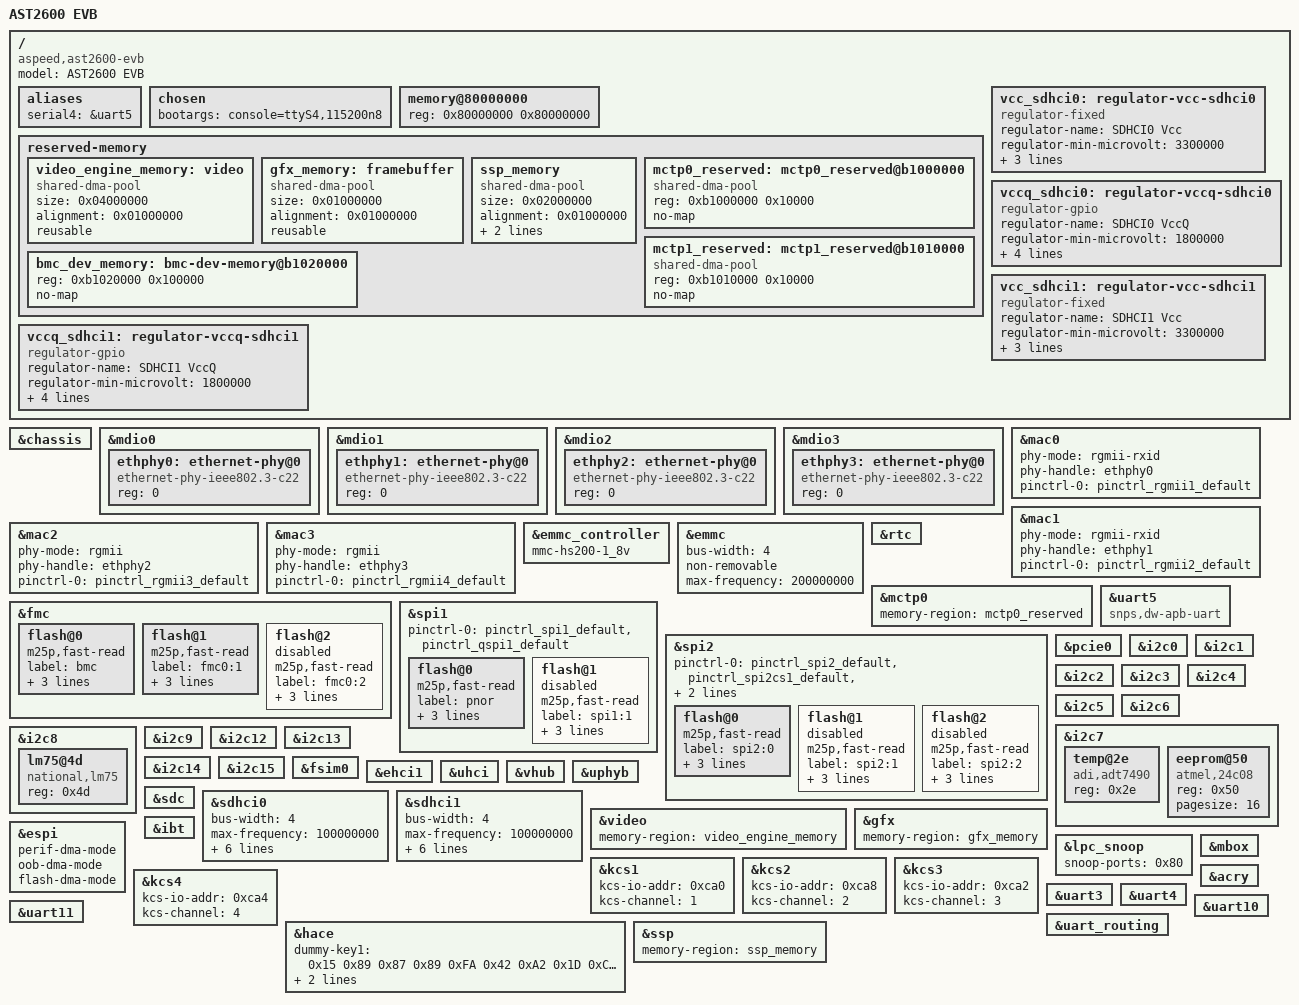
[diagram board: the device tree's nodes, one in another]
// SPDX-License-Identifier: GPL-2.0-or-later
// Copyright 2019 IBM Corp.

/dts-v1/;

#include "aspeed-g6.dtsi"
#include <dt-bindings/gpio/aspeed-gpio.h>

/ {
	model = "AST2600 EVB";
	compatible = "aspeed,ast2600-evb", "aspeed,ast2600";

	aliases {
		serial4 = &uart5;
	};

	chosen {
		bootargs = "console=ttyS4,115200n8";
	};

	memory@80000000 {
		device_type = "memory";
		reg = <0x80000000 0x80000000>;
	};

	reserved-memory {
		#address-cells = <1>;
		#size-cells = <1>;
		ranges;

		video_engine_memory: video {
			size = <0x04000000>;
			alignment = <0x01000000>;
			compatible = "shared-dma-pool";
			reusable;
		};

		gfx_memory: framebuffer {
			size = <0x01000000>;
			alignment = <0x01000000>;
			compatible = "shared-dma-pool";
			reusable;
		};

		ssp_memory: ssp_memory {
			size = <0x02000000>;
			alignment = <0x01000000>;
			shm-size = <0x1000>;
			compatible = "shared-dma-pool";
			no-map;
		};

		mctp0_reserved: mctp0_reserved@b1000000 {
			reg = <0xb1000000 0x10000>;
			compatible = "shared-dma-pool";
			no-map;
		};

		mctp1_reserved: mctp1_reserved@b1010000 {
			reg = <0xb1010000 0x10000>;
			compatible = "shared-dma-pool";
			no-map;
		};

		bmc_dev_memory: bmc-dev-memory@b1020000 {
			reg = <0xb1020000 0x100000>;
			no-map;
		};
	};

	vcc_sdhci0: regulator-vcc-sdhci0 {
		compatible = "regulator-fixed";
		regulator-name = "SDHCI0 Vcc";
		regulator-min-microvolt = <3300000>;
		regulator-max-microvolt = <3300000>;
		gpios = <&gpio0 ASPEED_GPIO(V, 0) GPIO_ACTIVE_HIGH>;
		enable-active-high;
	};

	vccq_sdhci0: regulator-vccq-sdhci0 {
		compatible = "regulator-gpio";
		regulator-name = "SDHCI0 VccQ";
		regulator-min-microvolt = <1800000>;
		regulator-max-microvolt = <3300000>;
		gpios = <&gpio0 ASPEED_GPIO(V, 1) GPIO_ACTIVE_HIGH>;
		gpios-states = <1>;
		states = <3300000 1>,
			 <1800000 0>;
	};

	vcc_sdhci1: regulator-vcc-sdhci1 {
		compatible = "regulator-fixed";
		regulator-name = "SDHCI1 Vcc";
		regulator-min-microvolt = <3300000>;
		regulator-max-microvolt = <3300000>;
		gpios = <&gpio0 ASPEED_GPIO(V, 2) GPIO_ACTIVE_HIGH>;
		enable-active-high;
	};

	vccq_sdhci1: regulator-vccq-sdhci1 {
		compatible = "regulator-gpio";
		regulator-name = "SDHCI1 VccQ";
		regulator-min-microvolt = <1800000>;
		regulator-max-microvolt = <3300000>;
		gpios = <&gpio0 ASPEED_GPIO(V, 3) GPIO_ACTIVE_HIGH>;
		gpios-states = <1>;
		states = <3300000 1>,
			 <1800000 0>;
	};
};

&chassis {
	status = "okay";
};

&mdio0 {
	status = "okay";

	ethphy0: ethernet-phy@0 {
		compatible = "ethernet-phy-ieee802.3-c22";
		reg = <0>;
	};
};

&mdio1 {
	status = "okay";

	ethphy1: ethernet-phy@0 {
		compatible = "ethernet-phy-ieee802.3-c22";
		reg = <0>;
	};
};

&mdio2 {
	status = "okay";

	ethphy2: ethernet-phy@0 {
		compatible = "ethernet-phy-ieee802.3-c22";
		reg = <0>;
	};
};

&mdio3 {
	status = "okay";

	ethphy3: ethernet-phy@0 {
		compatible = "ethernet-phy-ieee802.3-c22";
		reg = <0>;
	};
};

&mac0 {
	status = "okay";

	phy-mode = "rgmii-rxid";
	phy-handle = <&ethphy0>;

	pinctrl-names = "default";
	pinctrl-0 = <&pinctrl_rgmii1_default>;
};


&mac1 {
	status = "okay";

	phy-mode = "rgmii-rxid";
	phy-handle = <&ethphy1>;

	pinctrl-names = "default";
	pinctrl-0 = <&pinctrl_rgmii2_default>;
};

&mac2 {
	status = "okay";

	phy-mode = "rgmii";
	phy-handle = <&ethphy2>;

	pinctrl-names = "default";
	pinctrl-0 = <&pinctrl_rgmii3_default>;
};

&mac3 {
	status = "okay";

	phy-mode = "rgmii";
	phy-handle = <&ethphy3>;

	pinctrl-names = "default";
	pinctrl-0 = <&pinctrl_rgmii4_default>;
};

&emmc_controller {
	status = "okay";
	mmc-hs200-1_8v;
};

&emmc {
	status = "okay";
#if 1
	bus-width = <4>;
#else
	bus-width = <8>;
	pinctrl-0 = <&pinctrl_emmc_default
		     &pinctrl_emmcg8_default>;
#endif
	non-removable;
	max-frequency = <200000000>;
};

&rtc {
	status = "okay";
};

&mctp0 {
	status = "okay";
	memory-region = <&mctp0_reserved>;
};

&fmc {
	status = "okay";
	flash@0 {
		status = "okay";
		m25p,fast-read;
		label = "bmc";
		spi-rx-bus-width = <4>;
		spi-tx-bus-width = <4>;
		spi-max-frequency = <50000000>;
#include "aspeed-evb-flash-layout-64.dtsi"
	};

	flash@1 {
		status = "okay";
		m25p,fast-read;
		label = "fmc0:1";
		spi-rx-bus-width = <4>;
		spi-tx-bus-width = <4>;
		spi-max-frequency = <50000000>;
	};

	flash@2 {
		status = "disabled";
		m25p,fast-read;
		label = "fmc0:2";
		spi-rx-bus-width = <4>;
		spi-tx-bus-width = <4>;
		spi-max-frequency = <50000000>;
	};
};

&spi1 {
	status = "okay";
	pinctrl-names = "default";
	pinctrl-0 = <&pinctrl_spi1_default &pinctrl_qspi1_default>;

	flash@0 {
		status = "okay";
		m25p,fast-read;
		label = "pnor";
		spi-rx-bus-width = <4>;
		spi-tx-bus-width = <4>;
		spi-max-frequency = <100000000>;
	};

	flash@1 {
		status = "disabled";
		m25p,fast-read;
		label = "spi1:1";
		spi-rx-bus-width = <4>;
		spi-tx-bus-width = <4>;
		spi-max-frequency = <50000000>;
	};
};

&spi2 {
	status = "okay";
	pinctrl-names = "default";
	pinctrl-0 = <&pinctrl_spi2_default &pinctrl_spi2cs1_default
				 &pinctrl_spi2cs2_default &pinctrl_qspi2_default>;

	flash@0 {
		status = "okay";
		m25p,fast-read;
		label = "spi2:0";
		spi-tx-bus-width = <4>;
		spi-rx-bus-width = <4>;
		spi-max-frequency = <50000000>;
	};

	flash@1 {
		status = "disabled";
		m25p,fast-read;
		label = "spi2:1";
		spi-tx-bus-width = <4>;
		spi-rx-bus-width = <4>;
		spi-max-frequency = <50000000>;
	};

	flash@2 {
		status = "disabled";
		m25p,fast-read;
		label = "spi2:2";
		spi-tx-bus-width = <4>;
		spi-rx-bus-width = <4>;
		spi-max-frequency = <50000000>;
	};
};

&uart5 {
	// Workaround for A0
	compatible = "snps,dw-apb-uart";
};

#if 0
&bmc_dev {
	status = "okay";
	memory-region = <&bmc_dev_memory>;
};
#endif

&pcie0 {
	status = "okay";
};

&i2c0 {
	status = "okay";
};

&i2c1 {
	status = "okay";
};

&i2c2 {
	status = "okay";
};

&i2c3 {
	status = "okay";
};

&i2c4 {
	status = "okay";
};

&i2c5 {
	status = "okay";
};

&i2c6 {
	status = "okay";
};

&i2c7 {
	status = "okay";

	temp@2e {
		compatible = "adi,adt7490";
		reg = <0x2e>;
	};

	eeprom@50 {
		compatible = "atmel,24c08";
		reg = <0x50>;
		pagesize = <16>;
	};
};

&i2c8 {
	status = "okay";

	lm75@4d {
		compatible = "national,lm75";
		reg = <0x4d>;
	};
};

&i2c9 {
	status = "okay";
};

&i2c12 {
	status = "okay";
};

&i2c13 {
	status = "okay";
};

&i2c14 {
	status = "okay";
};

&i2c15 {
	status = "okay";
};

&fsim0 {
	status = "okay";
};

#if 0
&ehci0 {
	status = "okay";
};
#endif

&ehci1 {
	status = "okay";
};

&uhci {
	status = "okay";
};

&vhub {
	status = "okay";
	pinctrl-names = "default";
#if 0
	pinctrl-0 = <&pinctrl_usb2adp_default>;
#endif
};

#if 0
&udc {
	status = "okay";
	pinctrl-names = "default";
	pinctrl-0 = <&pinctrl_usb2bd_default>;
};
#endif

&uphyb {
	status = "okay";
};

&sdc {
	status = "okay";
};

/*
 * The signal voltage of sdhci0 and sdhci1 on AST2600-A2 EVB is able to be
 * toggled by GPIO pins.
 * In the reference design, GPIOV0 of AST2600-A2 EVB is connected to the
 * power load switch that provides 3.3v to sdhci0 vdd, GPIOV1 is connected to
 * a 1.8v and a 3.3v power load switch that provides signal voltage to
 * sdhci0 bus.
 * If GPIOV0 is active high, sdhci0 is enabled, otherwise, sdhci0 is disabled.
 * If GPIOV1 is active high, 3.3v power load switch is enabled, sdhci0 signal
 * voltage is 3.3v, otherwise, 1.8v power load switch will be enabled,
 * sdhci0 signal voltage becomes 1.8v.
 * AST2600-A2 EVB also supports toggling signal voltage for sdhci1.
 * The design is the same as sdhci0, it uses GPIOV2 as power-gpio and GPIOV3
 * as power-switch-gpio.
 */
&sdhci0 {
	status = "okay";
	bus-width = <4>;
	max-frequency = <100000000>;
	sdhci-drive-type = /bits/ 8 <3>;
	sdhci-caps-mask = <0x7 0x0>;
	sdhci,wp-inverted;
	vmmc-supply = <&vcc_sdhci0>;
	vqmmc-supply = <&vccq_sdhci0>;
	clk-phase-sd-hs = <7>, <200>;
};

&sdhci1 {
	status = "okay";
	bus-width = <4>;
	max-frequency = <100000000>;
	sdhci-drive-type = /bits/ 8 <3>;
	sdhci-caps-mask = <0x7 0x0>;
	sdhci,wp-inverted;
	vmmc-supply = <&vcc_sdhci1>;
	vqmmc-supply = <&vccq_sdhci1>;
	clk-phase-sd-hs = <7>, <200>;
};

&video {
	status = "okay";
	memory-region = <&video_engine_memory>;
};

&gfx {
	status = "okay";
	memory-region = <&gfx_memory>;
};

&espi {
	status = "okay";
	perif-dma-mode;
	oob-dma-mode;
	flash-dma-mode;
};

#if 1
&lpc_snoop {
	status = "okay";
	snoop-ports = <0x80>;
};
#else
&lpc_pcc {
	status = "okay";
	pcc-ports = <0x80>;
};
#endif

&ibt {
	status = "okay";
};

&kcs1 {
	kcs-io-addr = <0xca0>;
	kcs-channel = <1>;
	status = "okay";
};

&kcs2 {
	kcs-io-addr = <0xca8>;
	kcs-channel = <2>;
	status = "okay";
};

&kcs3 {
	status = "okay";
	kcs-io-addr = <0xca2>;
	kcs-channel = <3>;
};

&kcs4 {
	status = "okay";
	kcs-io-addr = <0xca4>;
	kcs-channel = <4>;
};

&mbox {
	status = "okay";
};

&hace {
	status = "okay";
	dummy-key1 = /bits/ 8 <0x15 0x89 0x87 0x89 0xFA 0x42 0xA2 0x1D 0xCE 0x85 0x78 0x1A 0x39 0xFA 0xD7 0x5B 0xFD 0x65 0x32 0xC5 0x25 0x6B 0x34 0xCC 0xEE 0x70 0x03 0x23 0x29 0x06 0x57 0xD0>;
	dummy-key2 = /bits/ 8 <0x02 0x89 0x87 0x89 0xFA 0x42 0xA2 0x1D 0xCE 0x85 0x78 0x1A 0x39 0xFA 0xD7 0x5B 0xFD 0x65 0x32 0xC5 0x25 0x6B 0x34 0xCC 0xEE 0x70 0x03 0x23 0x29 0x06 0x57 0xD0>;
};

&acry {
	status = "okay";
};

&uart3 {
	status = "okay";
};

&uart4 {
	status = "okay";
};

&uart10 {
	status = "okay";
};

&uart11 {
	status = "okay";
};

&uart_routing {
	status = "okay";
};

#if 0
&vuart1 {
	virtual;
	port = <0x3f8>;
	sirq = <4>;
	sirq-polarity = <0>;
	status = "okay";
};
#endif

&ssp {
	memory-region = <&ssp_memory>;
};
